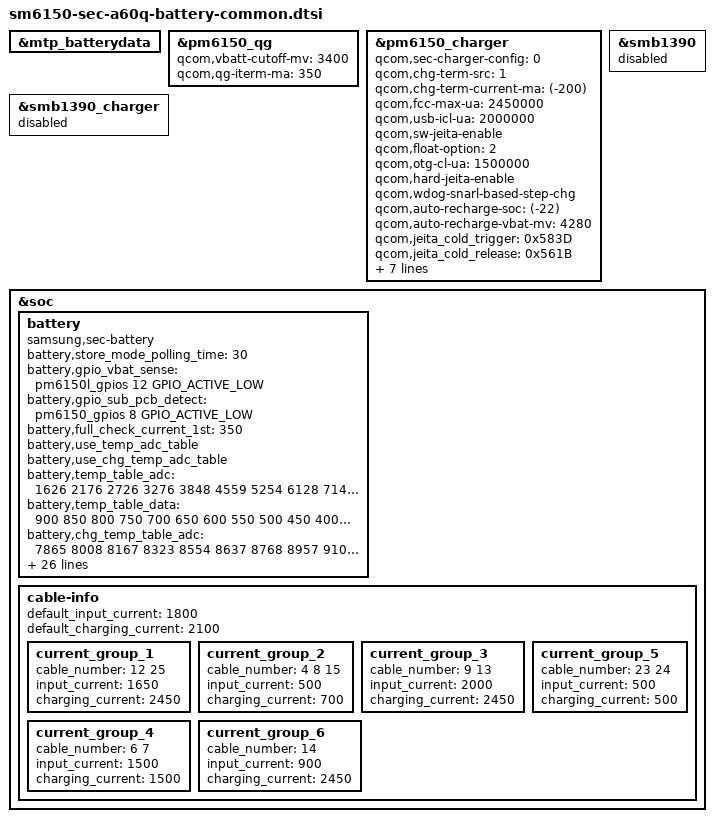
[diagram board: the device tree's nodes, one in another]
/* Copyright (c) 2014, The Linux Foundation. All rights reserved.
 *
 * This program is free software; you can redistribute it and/or modify
 * it under the terms of the GNU General Public License version 2 and
 * only version 2 as published by the Free Software Foundation.
 *
 * This program is distributed in the hope that it will be useful,
 * but WITHOUT ANY WARRANTY; without even the implied warranty of
 * MERCHANTABILITY or FITNESS FOR A PARTICULAR PURPOSE.  See the
 * GNU General Public License for more details.
 */

&mtp_batterydata {
	/delete-node/ qcom,alium_860_89032_0000_3600mAh;
	/delete-node/ qcom,mlp356477_2800mah;
	#include "sm6150-sec-qg-batterydata-a60q.dtsi"
};

&pm6150_qg {
	qcom,vbatt-cutoff-mv = <3400>;	/* SOC 0% */
	qcom,qg-iterm-ma = <350>;		/* SOC 100% */
};

&pm6150_charger {
	/delete-property/ qcom,sec-charger-config;
	/delete-property/ qcom,step-charging-enable;
	qcom,sec-charger-config = <0>;
	qcom,chg-term-src = <1>;	/* 0 : 	ITERM_SRC_UNSPECIFIED, 1 : ITERM_SRC_ADC, 2 : ITERM_SRC_ANALOG */
	qcom,chg-term-current-ma = <(-200)>;
	qcom,fcc-max-ua = <2450000>;
	qcom,usb-icl-ua = <2000000>;
	qcom,sw-jeita-enable;
	qcom,float-option = <2>;
	qcom,otg-cl-ua = <1500000>;
	qcom,hard-jeita-enable;
	qcom,wdog-snarl-based-step-chg;
	qcom,auto-recharge-soc = <(-22)>;
	qcom,auto-recharge-vbat-mv = <4280>;

	qcom,jeita_cold_trigger = <0x583D>;		/* 0 degree */
	qcom,jeita_cold_release = <0x561B>;		/* 2 degree */
	qcom,jeita_hot_trigger = <0x1BE6>;		/* 50 degree */
	qcom,jeita_hot_release = <0x1DE0>;		/* 48 degree */

	/* Adding for SBUx short & water detection */
	pinctrl-names = "default";
	pinctrl-0 = <&hiccup_default>;
	hiccup-gpio = <&pm6150_gpios 4 GPIO_ACTIVE_LOW>;
	water-det-enable;
	#sbu-short-detect-enable;

	rid-gnd-gpio = <&pm6150l_gpios 9 GPIO_ACTIVE_LOW>;
};

&smb1390 {
    status = "disabled";
};

&smb1390_charger {
    status = "disabled";
};

&soc {
	battery {
		status = "okay";
		compatible = "samsung,sec-battery";
		battery,store_mode_polling_time = <30>;
		battery,gpio_vbat_sense = <&pm6150l_gpios 12 GPIO_ACTIVE_LOW>;
		battery,gpio_sub_pcb_detect = <&pm6150_gpios 8 GPIO_ACTIVE_LOW>;
		battery,full_check_current_1st = <350>;
		battery,use_temp_adc_table;
		battery,use_chg_temp_adc_table;

		battery,temp_table_adc = <1626 2176 2726 3276 3848
						4559 5254 6128 7142 8408
						9805 11278 12866 14532 16212
						17869 19637 21224 22589 23882
						25002 25885 26599>;
		battery,temp_table_data = <900 850 800 750 700
						650 600 550 500 450
						400 350 300 250 200
						150 100 50 0 (-50)
						(-100) (-150) (-200)>;

		battery,chg_temp_table_adc = <7865 8008 8167 8323 8554
						8637 8768 8957 9103 9261
						9412 9569 9720 9892 10060
						10217 10377 10529 10707 10865
						11025 11185 11345>;
		battery,chg_temp_table_data = <(-200) (-150) (-100) (-50) 0
						50 100 150 200 250
						300 350 400 450 500
						550 600 650 700 750
						800 850 900>;

		/* mix temp setting value */
		battery,mix_temp_recovery = <390>;
		battery,mix_temp_batt_threshold = <420>;
		battery,mix_temp_die_threshold = <700>;

		/* chg temp setting value */
		battery,chg_high_temp = <520>;
		battery,chg_high_temp_recovery = <500>;
		battery,chg_input_limit_current = <1000>;
		battery,chg_charging_limit_current = <1250>;

		/* Safety timer parameters */
		battery,standard_curr = <2450000>;		//equal to last step of step_chg_ranges
		battery,expired_time = <11400>;		//190min
		battery,recharging_expired_time = <5400>;	//90mins
		battery,safety_timer_polling_time = <30>;

		battery,battery_full_capacity = <3400>; /* battery capacity */
		/* disable Vbat ovp dettection */
		battery,cisd_max_voltage_thr = <5000>; /* batttery ovp dettection voltage */
		battery,cisd_alg_index = <7>;

		battery,siop_input_limit_current = <1200>;
		battery,siop_charging_limit_current = <1800>;
		battery,siop_hv_input_limit_current = <700>;
		battery,siop_hv_charging_limit_current = <1800>;
		battery,minimum_hv_input_current_by_siop_10 = <400>;

		battery,ttf_hv_charge_current = <2240>;

		battery,ttf_capacity = <3000>;
		battery,cv_data = <
					2476	747	2401
					2406	761	2339
					2292	774	2276
					2198	787	2214
					2129	800	2150
					2031	811	2087
					1934	823	2024
					1860	833	1962
					1766	844	1899
					1685	853	1837
					1615	862	1774
					1548	871	1711
					1472	880	1643
					1412	887	1586
					1356	895	1520
					1284	902	1460
					1222	908	1397
					1173	915	1334
					1127	921	1272
					1067	926	1202
					1022	932	1145
					988	937	1079
					944	942	1014
					906	946	957
					870	951	892
					827	955	826
					791	959	769
					759	963	704
					725	966	639
					701	970	581
					670	973	516
					642	976	451
					621	979	394
					592	982	328
					568	985	263
					540	987	198
					516	990	180
					478	994	105
					420	1000	0
					>;
	};

/* sec_battery_cable
 *   0	UNKNOWN,
 *   1	BATTERY,
 *   2	UPS,
 *   3	MAINS,
 *   4	USB,
 *   5	USB_DCP,
 *   6	USB_CDP,
 *   7	USB_ACA,
 *   8	USB_TYPE_C,
 *   9	USB_PD,
 *  10	USB_PD_DRP,
 *  11	APPLE_BRICK_ID,
 *  12	USB_HVDCP,
 *  13	USB_HVDCP_3,
 *  14	WIRELESS,
 *  15	USB_FLOAT,
 *  16	BMS,
 *  17	PARALLEL,
 *  18	MAIN,
 *  19	WIPOWER,
 *  20	UFP,
 *  21	DFP,
 *  22	CHARGE_PUMP,
 *  23	POWER_SHARING,
 *  24	OTG,
 *  25	AFC,
 *  26	CABLE_MAX,
*/
	cable-info {
		default_input_current = <1800>;
		default_charging_current = <2100>;

		current_group_1 {
			cable_number = <12 25>;
			input_current = <1650>;
			charging_current = <2450>;
		};
		current_group_2 {
			cable_number = <4 8 15>;
			input_current = <500>;
			charging_current = <700>;
		};
		current_group_3 {
			cable_number = <9 13>;
			input_current = <2000>;
			charging_current = <2450>;
		};
		current_group_4 {
			cable_number = <6 7>;
			input_current = <1500>;
			charging_current = <1500>;
		};
		current_group_5 {
			cable_number = <23 24>;
			input_current = <500>;
			charging_current = <500>;
		};
		current_group_6 {
			cable_number = <14>;
			input_current = <900>;
			charging_current = <2450>;
		};
	};
};
